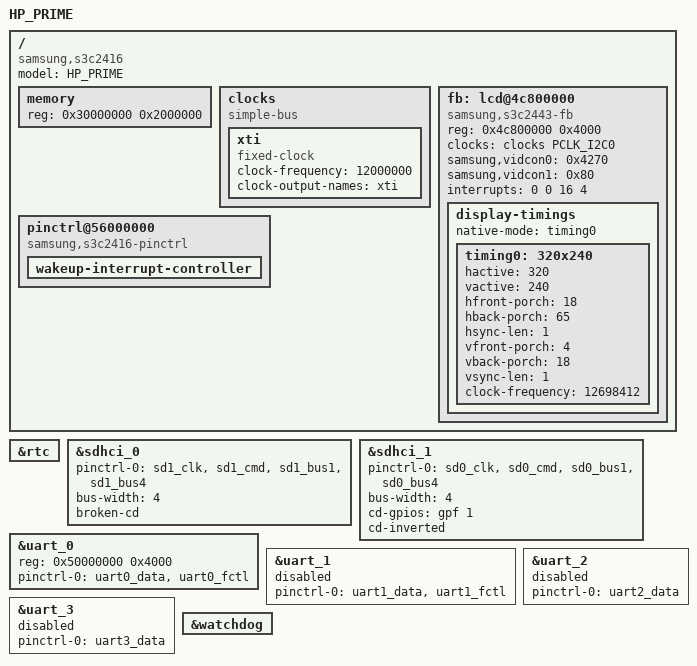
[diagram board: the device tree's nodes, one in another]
/*
 * SAMSUNG SMDK2416 board device tree source
 *
 * Copyright (c) 2013 Heiko Stuebner <heiko@sntech.de>
 *
 * This program is free software; you can redistribute it and/or modify
 * it under the terms of the GNU General Public License version 2 as
 * published by the Free Software Foundation.
 */

/dts-v1/;
#include "s3c2416.dtsi"

/ {
	model = "HP_PRIME";
	compatible = "samsung,s3c2416", "hp,hp_prime";

	memory {
		reg =  <0x30000000 0x2000000>;
	};

	clocks {
		compatible = "simple-bus";
		#address-cells = <1>;
		#size-cells = <1>;

		xti: xti {
			compatible = "fixed-clock";
			clock-frequency = <12000000>;
			clock-output-names = "xti";
			#clock-cells = <0>;
		};
	};
	// eventually, FB will be set up to work with DT, but not yet
	fb: lcd@4c800000 {
		reg = <0x4c800000 0x4000>;
		compatible = "samsung,s3c2443-fb";
		clocks = <&clocks PCLK_I2C0>;
		clock-names = "i2c";
		samsung,vidcon0 = <0x4270>;
		samsung,vidcon1 = <0x80>;
		interrupts = <0 0 16 4>;
		display-timings {
			native-mode = <&timing0>;
			timing0: 320x240 {
				hactive		= <320>;
				vactive		= <240>;
				hfront-porch	= <18>;
				hback-porch	= <65>;
				hsync-len	= <1>;
				vfront-porch	= <4>;
				vback-porch	= <18>;
				vsync-len	= <1>;
				clock-frequency = <12698412>;
			};
		};
	};
	pinctrl@56000000 {
		compatible = "samsung,s3c2416-pinctrl";
		wakeup-interrupt-controller {
			compatible = ""; // this doesn't seem to anything on the Prime
		};
	};
};

&rtc {
	status = "okay";
};

&sdhci_0 {
	pinctrl-names = "default";
	pinctrl-0 = <&sd1_clk>, <&sd1_cmd>,
			<&sd1_bus1>, <&sd1_bus4>;
	bus-width = <4>;
	broken-cd;
	status = "okay";
};

&sdhci_1 {
	pinctrl-names = "default";
	pinctrl-0 = <&sd0_clk>, <&sd0_cmd>,
			<&sd0_bus1>, <&sd0_bus4>;
	bus-width = <4>;
	cd-gpios = <&gpf 1 0>;
	cd-inverted;
	status = "okay";
};

&uart_0 {
	status = "okay";
    reg = <0x50000000 0x4000>;
	pinctrl-names = "default";
	pinctrl-0 = <&uart0_data>, <&uart0_fctl>;
};

&uart_1 {
	status = "disabled";
	pinctrl-names = "default";
	pinctrl-0 = <&uart1_data>, <&uart1_fctl>;
};

&uart_2 {
	status = "disabled";
	pinctrl-names = "default";
	pinctrl-0 = <&uart2_data>;
};

&uart_3 {
	status = "disabled";
	pinctrl-names = "default";
	pinctrl-0 = <&uart3_data>;
};

&watchdog {
	status = "okay";
};
